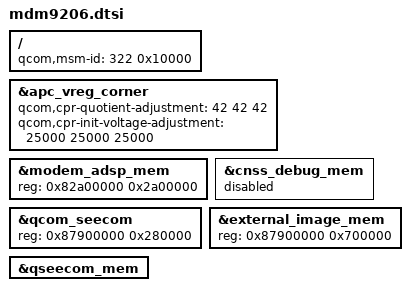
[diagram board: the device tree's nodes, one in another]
/*
 * Copyright (c) 2017, The Linux Foundation. All rights reserved.
 *
 * This program is free software; you can redistribute it and/or modify
 * it under the terms of the GNU General Public License version 2 and
 * only version 2 as published by the Free Software Foundation.
 *
 * This program is distributed in the hope that it will be useful,
 * but WITHOUT ANY WARRANTY; without even the implied warranty of
 * MERCHANTABILITY or FITNESS FOR A PARTICULAR PURPOSE.  See the
 * GNU General Public License for more details.
 */


/ {
	qcom,msm-id = <322 0x10000>;
};

&apc_vreg_corner {
	qcom,cpr-quotient-adjustment =
			<42	42	42>;
	qcom,cpr-init-voltage-adjustment =
			<25000	25000	25000>;
};

&modem_adsp_mem {
	reg = <0x82a00000 0x2a00000>;
};

&cnss_debug_mem {
	status = "disabled";
};

&qcom_seecom {
	reg = <0x87900000 0x280000>;
	status = "okay";
};

&external_image_mem {
	reg = <0x87900000 0x700000>;
};

&qseecom_mem {
	status = "okay";
};
